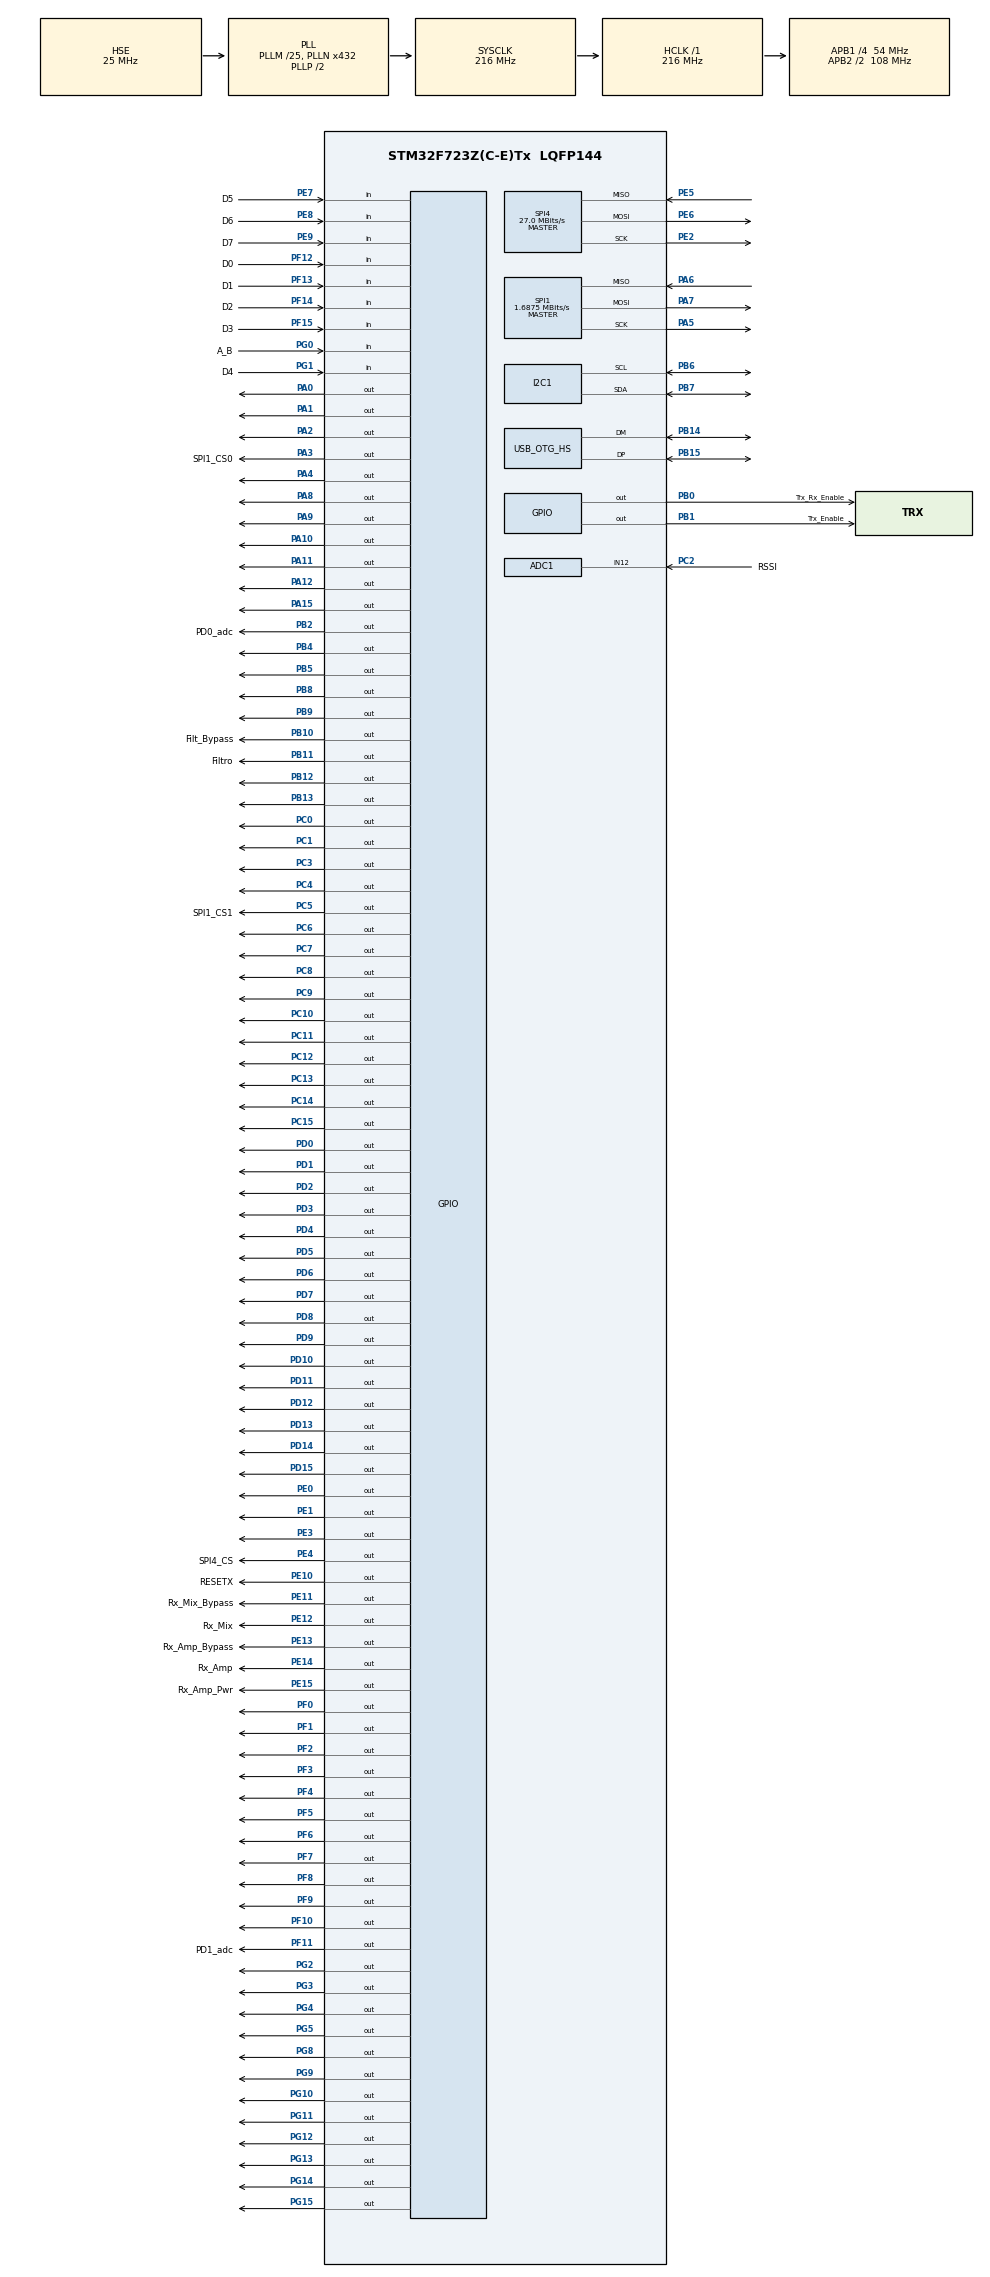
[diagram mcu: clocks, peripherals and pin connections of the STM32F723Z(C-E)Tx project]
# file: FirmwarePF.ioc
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PH0-OSC_IN.Signal=RCC_OSC_IN
SPI4.VirtualType=VM_MASTER
NVIC.I2C1_EV_IRQn=true\:0\:0\:false\:false\:true\:true\:true
SPI1.VirtualType=VM_MASTER
PG4.Signal=GPIO_Output
PG8.Signal=GPIO_Output
PC12.Signal=GPIO_Output
PG0.Signal=GPIO_Input
PA3.GPIO_Speed=GPIO_SPEED_FREQ_VERY_HIGH
PB13.Signal=GPIO_Output
PG13.Signal=GPIO_Output
RCC.SYSCLKSource=RCC_SYSCLKSOURCE_PLLCLK
PF7.Signal=GPIO_Output
SPI1.Direction=SPI_DIRECTION_2LINES
PE2.Mode=Full_Duplex_Master
PD4.Signal=GPIO_Output
RCC.APB2TimFreq_Value=216000000
PB6.Signal=I2C1_SCL
PC7.Signal=GPIO_Output
PB6.Mode=I2C
SPI1.CalculateBaudRate=1.6875 MBits/s
PC3.Signal=GPIO_Output
PD0.Signal=GPIO_Output
PD8.Signal=GPIO_Output
PE5.Signal=SPI4_MISO
PE1.Signal=GPIO_Output
PB2.Signal=GPIO_Output
PB3.Mode=Trace_Asynchronous_SW
PF12.GPIO_Label=D0
PE9.Signal=GPIO_Input
PB14.Mode=Internal_Phy_Device
PB1.GPIO_Label=Trx_Enable
SPI1.DataSize=SPI_DATASIZE_8BIT
PE4.GPIO_Label=SPI4_CS
PE2.Signal=SPI4_SCK
PA8.Signal=GPIO_Output
PF3.Signal=GPIO_Output
NVIC.I2C1_ER_IRQn=true\:0\:0\:false\:false\:true\:true\:true
PE10.Signal=GPIO_Output
Mcu.Package=LQFP144
PB9.Signal=GPIO_Output
PB1.Signal=GPIO_Output
PD12.Signal=GPIO_Output
PA10.Signal=GPIO_Output
PE12.GPIO_Label=Rx_Mix
RCC.APB2CLKDivider=RCC_HCLK_DIV2
PF14.Signal=GPIO_Input
RCC.APB1TimFreq_Value=108000000
PE10.GPIO_Label=RESETX
PD15.Signal=GPIO_Output
NVIC.RCC_IRQn=true\:0\:0\:false\:false\:true\:true\:false
PA5.Mode=Full_Duplex_Master
PG12.Signal=GPIO_Output
REXTPHYHS.Signal=USB_OTG_HS_REXTPHYHS
PG5.Signal=GPIO_Output
PG9.Signal=GPIO_Output
PC13.Signal=GPIO_Output
PD3.Signal=GPIO_Output
PC2.Signal=ADCx_IN12
PC6.Signal=GPIO_Output
PB11.GPIO_Label=Filtro
PD7.Signal=GPIO_Output
PD1.Signal=GPIO_Output
PF14.GPIO_Label=D2
PC0.Signal=GPIO_Output
RCC.APB1CLKDivider=RCC_HCLK_DIV4
PC14-OSC32_IN.Signal=GPIO_Output
PF13.GPIO_Label=D1
PA0-WKUP.Signal=GPIO_Output
PG10.Signal=GPIO_Output
PD10.Signal=GPIO_Output
PE8.GPIO_Label=D6
PA9.Signal=GPIO_Output
I2C1.Timing=0x20404768
PE9.GPIO_Label=D7
SPI4.NSSPMode=SPI_NSS_PULSE_DISABLE
PB10.Signal=GPIO_Output
PB14.Signal=USB_OTG_HS_DM
PA5.Signal=SPI1_SCK
NVIC.SPI1_IRQn=true\:0\:0\:false\:false\:true\:true\:true
PE14.Signal=GPIO_Output
PE6.Mode=Full_Duplex_Master
PE15.Signal=GPIO_Output
PE8.Signal=GPIO_Input
SPI1.Mode=SPI_MODE_MASTER
PF13.Signal=GPIO_Input
PA13.Mode=Trace_Asynchronous_SW
SPI1.NSSPMode=SPI_NSS_PULSE_DISABLE
PA4.Signal=GPIO_Output
PB5.Signal=GPIO_Output
ADC1.master=1
PE13.GPIO_Label=Rx_Amp_Bypass
PD11.Signal=GPIO_Output
PA11.Signal=GPIO_Output
ProjectManager.HeapSize=0x200
PF9.Signal=GPIO_Output
NVIC.PriorityGroup=NVIC_PRIORITYGROUP_4
PC5.GPIO_Speed=GPIO_SPEED_FREQ_VERY_HIGH
PE3.Signal=GPIO_Output
PE4.PinState=GPIO_PIN_SET
PA3.PinState=GPIO_PIN_SET
PF4.Signal=GPIO_Output
PD2.Signal=GPIO_Output
PB0.Signal=GPIO_Output
PC1.Signal=GPIO_Output
Mcu.Family=STM32F7
NVIC.OTG_HS_IRQn=true\:0\:0\:false\:false\:true\:false\:true
PA6.Mode=Full_Duplex_Master
VP_USB_DEVICE_VS_USB_DEVICE_CDC_HS.Mode=CDC_HS
RCC.CortexFreq_Value=216000000
PG2.Signal=GPIO_Output
PE11.GPIO_Label=Rx_Mix_Bypass
PC10.Signal=GPIO_Output
SPI4.Direction=SPI_DIRECTION_2LINES
PB0.GPIO_Label=Trx_Rx_Enable
PB11.Signal=GPIO_Output
PB15.Signal=USB_OTG_HS_DP
PG11.Signal=GPIO_Output
PG15.Signal=GPIO_Output
ProjectManager.StackSize=0x400
PD13.Signal=GPIO_Output
NVIC.ADC_IRQn=true\:0\:0\:false\:false\:true\:true\:true
PA12.Signal=GPIO_Output
SPI4.Mode=SPI_MODE_MASTER
ADC1.Channel-3\#ChannelRegularConversion=ADC_CHANNEL_12
RCC.HCLKFreq_Value=216000000
PF11.GPIO_Label=PD1_adc
PF12.Signal=GPIO_Input
USB_DEVICE.VirtualMode-CDC_HS=Cdc
RCC.AHBFreq_Value=216000000
PH0-OSC_IN.Mode=HSE-External-Clock-Source
RCC.HSE_VALUE=25000000
PE13.Signal=GPIO_Output
PA14.Mode=Trace_Asynchronous_SW
PE4.GPIO_Speed=GPIO_SPEED_FREQ_VERY_HIGH
PF11.Signal=GPIO_Output
PB7.Signal=I2C1_SDA
USB_OTG_HS.dma_enable=ENABLE
PE4.Signal=GPIO_Output
SPI4.BaudRatePrescaler=SPI_BAUDRATEPRESCALER_4
PH1-OSC_OUT.Mode=HSE-External-Clock-Source
PA6.Signal=SPI1_MISO
PA15.Signal=GPIO_Output
USB_DEVICE.CLASS_NAME_HS=CDC
PF8.Signal=GPIO_Output
PG0.GPIO_Label=A_B
PF5.Signal=GPIO_Output
USB_DEVICE.VirtualModeHS=Cdc_HS
PF0.Signal=GPIO_Output
PC5.Signal=GPIO_Output
PE7.Signal=GPIO_Input
PD6.Signal=GPIO_Output
SPI1.BaudRatePrescaler=SPI_BAUDRATEPRESCALER_64
PC2.GPIO_Label=RSSI
REXTPHYHS.Mode=Internal_Phy_Device
PB4.Signal=GPIO_Output
PA3.Signal=GPIO_Output
PA7.Mode=Full_Duplex_Master
SPI4.DataSize=SPI_DATASIZE_16BIT
PG3.Signal=GPIO_Output
PG1.Signal=GPIO_Input
PC11.Signal=GPIO_Output
PC8.Signal=GPIO_Output
PC4.Signal=GPIO_Output
PE14.GPIO_Label=Rx_Amp
PD9.Signal=GPIO_Output
PD5.Signal=GPIO_Output
PA13.Signal=SYS_JTMS-SWDIO
SH.ADCx_IN12.0=ADC1_IN12,IN12
PE15.GPIO_Label=Rx_Amp_Pwr
PF6.Signal=GPIO_Output
ProjectManager.TargetToolchain=STM32CubeIDE
PB10.GPIO_Label=Filt_Bypass
PF2.Signal=GPIO_Output
RCC.USBFreq_Value=48000000
PE11.Signal=GPIO_Output
RCC.LSE_VALUE=32768
PC15-OSC32_OUT.Signal=GPIO_Output
PA1.Signal=GPIO_Output
PG14.Signal=GPIO_Output
board=custom
RCC.VCOOutputFreq_Value=432000000
PG1.GPIO_Label=D4
PB15.Mode=Internal_Phy_Device
NVIC.OTG_HS_EP1_OUT_IRQn=true\:0\:0\:false\:false\:true\:true\:true
RCC.APB2Freq_Value=108000000
PF10.Signal=GPIO_Output
PE5.Mode=Full_Duplex_Master
USB_DEVICE.USBD_SELF_POWERED-CDC_HS=0
PH1-OSC_OUT.Signal=RCC_OSC_OUT
PF15.GPIO_Label=D3
PF15.Signal=GPIO_Input
SPI4.CalculateBaudRate=27.0 MBits/s
PF1.Signal=GPIO_Output
PE6.Signal=SPI4_MOSI
Mcu.Name=STM32F723Z(C-E)Tx
PE0.Signal=GPIO_Output
PE7.GPIO_Label=D5
PE12.Signal=GPIO_Output
PA2.Signal=GPIO_Output
NVIC.OTG_HS_EP1_IN_IRQn=true\:0\:0\:false\:false\:true\:true\:true
PD14.Signal=GPIO_Output
PB3.Signal=SYS_JTDO-SWO
RCC.SYSCLKFreq_VALUE=216000000
PC5.PinState=GPIO_PIN_SET
ADC1.Rank-3\#ChannelRegularConversion=1
ADC1.SamplingTime-3\#ChannelRegularConversion=ADC_SAMPLETIME_3CYCLES
USB_OTG_HS.VirtualMode=Int_Phy_Device
PC5.GPIO_Label=SPI1_CS1
USB_DEVICE.USBD_LPM_ENABLED-CDC_HS=0
PB7.Mode=I2C
PA14.Signal=SYS_JTCK-SWCLK
PB2.GPIO_Label=PD0_adc
RCC.HSI_VALUE=16000000
RCC.PLLQ=9
ADC1.NbrOfConversionFlag=1
RCC.PLLM=25
RCC.PLLN=432
PB8.Signal=GPIO_Output
PC9.Signal=GPIO_Output
RCC.APB1Freq_Value=54000000
PB12.Signal=GPIO_Output
PA3.GPIO_Label=SPI1_CS0
PA7.Signal=SPI1_MOSI

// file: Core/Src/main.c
/* USER CODE BEGIN Header */
/**
  ******************************************************************************
  * @file           : main.c
  * @brief          : Main program body
  ******************************************************************************
  * @attention
  *
  * <h2><center>&copy; Copyright (c) 2021 STMicroelectronics.
  * All rights reserved.</center></h2>
  *
  * This software component is licensed by ST under Ultimate Liberty license
  * SLA0044, the "License"; You may not use this file except in compliance with
  * the License. You may obtain a copy of the License at:
  *                             www.st.com/SLA0044
  *
  ******************************************************************************
  */
/* USER CODE END Header */
#include "main.h"
#include "usb_device.h"

/* USER CODE BEGIN Includes */
#include "usbd_cdc_if.h"
/*#include "gen_clock.h"
#include "max2837.h"
#include "rffc5072.h"
#include "utils.h"*/
//#include "i2c-lcd.h"
/* USER CODE END Includes */

ADC_HandleTypeDef hadc1;

I2C_HandleTypeDef hi2c1;

SPI_HandleTypeDef hspi1;
SPI_HandleTypeDef hspi4;

/* USER CODE BEGIN PV */
genclk_st clockg;
max2837_st transceiver;
rffc5072_st mixer;

uint8_t max2837_temperature;
uint16_t max2837_rssi;
/* USER CODE END PV */

void SystemClock_Config(void);
static void MX_GPIO_Init(void);
static void MX_SPI1_Init(void);
static void MX_I2C1_Init(void);
static void MX_SPI4_Init(void);
static void MX_ADC1_Init(void);

/* USER CODE BEGIN 0 */
void HAL_SPI_TxCpltCallback(SPI_HandleTypeDef *hspi){
	if(mixer.mixer_read_flg){
		if((HAL_SPI_Receive_IT(mixer.spiHandle, mixer.rxDataBuf, sizeof(mixer.rxDataBuf))) == HAL_OK){
		}
		else{
			mixer.mixer_read_flg = 0;
			spi_disable(mixer.CS_bank, mixer.CS_pin);
			//lcd_send_string("Mix_r_err SPI Rx");
		}
	}
	else if(mixer.mixer_write_flg){
		mixer.mixer_write_flg = 0;
		mixer.regs_values[mixer.current_addr] = mixer.txData_temp;
		spi_disable(mixer.CS_bank, mixer.CS_pin);
	}

	if(transceiver.transceiver_write_flg){
		transceiver.transceiver_write_flg = 0;
		transceiver.regs_values[transceiver.current_addr] = transceiver.txData_temp;
		spi_disable(transceiver.CS_bank, transceiver.CS_pin);
	}
}

void HAL_SPI_RxCpltCallback(SPI_HandleTypeDef *hspi){
	if(mixer.mixer_read_flg){
		mixer.regs_values[mixer.current_addr] = (mixer.rxDataBuf[0] << 8) | mixer.rxDataBuf[1];
		mixer.mixer_read_flg = 0;
		spi_disable(mixer.CS_bank, mixer.CS_pin);
	}
}

void HAL_SPI_TxRxCpltCallback(SPI_HandleTypeDef *hspi){
	if(transceiver.transceiver_read_flg){
		transceiver.transceiver_read_flg = 0;
		transceiver.regs_values[transceiver.current_addr] = (transceiver.rxDataBuf[1] << 2) | transceiver.rxDataBuf[2];
		spi_disable(transceiver.CS_bank, transceiver.CS_pin);
	}
}

/* USER CODE END 0 */

int main(void)
{

  /* MCU Configuration--------------------------------------------------------*/

  /* Reset of all peripherals, Initializes the Flash interface and the Systick. */
  HAL_Init();

  /* Configure the system clock */
  SystemClock_Config();

  /* Initialize all configured peripherals */
  MX_GPIO_Init();
  MX_SPI1_Init();
  MX_USB_DEVICE_Init();
  MX_I2C1_Init();
  MX_SPI4_Init();
  MX_ADC1_Init();
  /* USER CODE BEGIN 2 */

  gpio_init();
  genclk_init(&clockg, &hi2c1);
  max2837_init(&transceiver, &hspi1, SPI1_CS1_GPIO_Port, SPI1_CS1_Pin, Trx_Enable_GPIO_Port, Trx_Enable_Pin, Trx_Rx_Enable_Pin);
  rffc5072_init(&mixer, &hspi1, SPI1_CS0_GPIO_Port, SPI1_CS0_Pin);
  //lcd_init();
  genclk_fod_settings(&clockg, 1, 24);
  HAL_Delay(200);
  genclk_fod_settings(&clockg, 2, 43);
  HAL_Delay(200);
  genclk_fod_settings(&clockg, 3, 38);
  HAL_Delay(200);
  genclk_fod_settings(&clockg, 4, 49);

  /* USER CODE END 2 */

  /* Infinite loop */
  while (1)
  {

  }
}

void SystemClock_Config(void)
{
  RCC_OscInitTypeDef RCC_OscInitStruct = {0};
  RCC_ClkInitTypeDef RCC_ClkInitStruct = {0};
  RCC_PeriphCLKInitTypeDef PeriphClkInitStruct = {0};

  /** Configure the main internal regulator output voltage
  */
  __HAL_RCC_PWR_CLK_ENABLE();
  __HAL_PWR_VOLTAGESCALING_CONFIG(PWR_REGULATOR_VOLTAGE_SCALE1);
  /** Initializes the RCC Oscillators according to the specified parameters
  * in the RCC_OscInitTypeDef structure.
  */
  RCC_OscInitStruct.OscillatorType = RCC_OSCILLATORTYPE_HSE;
  RCC_OscInitStruct.HSEState = RCC_HSE_BYPASS;
  RCC_OscInitStruct.PLL.PLLState = RCC_PLL_ON;
  RCC_OscInitStruct.PLL.PLLSource = RCC_PLLSOURCE_HSE;
  RCC_OscInitStruct.PLL.PLLM = 25;
  RCC_OscInitStruct.PLL.PLLN = 432;
  RCC_OscInitStruct.PLL.PLLP = RCC_PLLP_DIV2;
  RCC_OscInitStruct.PLL.PLLQ = 9;
  if (HAL_RCC_OscConfig(&RCC_OscInitStruct) != HAL_OK)
  {
    Error_Handler();
  }
  /** Activate the Over-Drive mode
  */
  if (HAL_PWREx_EnableOverDrive() != HAL_OK)
  {
    Error_Handler();
  }
  /** Initializes the CPU, AHB and APB buses clocks
  */
  RCC_ClkInitStruct.ClockType = RCC_CLOCKTYPE_HCLK|RCC_CLOCKTYPE_SYSCLK
                              |RCC_CLOCKTYPE_PCLK1|RCC_CLOCKTYPE_PCLK2;
  RCC_ClkInitStruct.SYSCLKSource = RCC_SYSCLKSOURCE_PLLCLK;
  RCC_ClkInitStruct.AHBCLKDivider = RCC_SYSCLK_DIV1;
  RCC_ClkInitStruct.APB1CLKDivider = RCC_HCLK_DIV4;
  RCC_ClkInitStruct.APB2CLKDivider = RCC_HCLK_DIV2;

  if (HAL_RCC_ClockConfig(&RCC_ClkInitStruct, FLASH_LATENCY_7) != HAL_OK)
  {
    Error_Handler();
  }
  PeriphClkInitStruct.PeriphClockSelection = RCC_PERIPHCLK_I2C1|RCC_PERIPHCLK_CLK48;
  PeriphClkInitStruct.I2c1ClockSelection = RCC_I2C1CLKSOURCE_PCLK1;
  PeriphClkInitStruct.Clk48ClockSelection = RCC_CLK48SOURCE_PLL;
  if (HAL_RCCEx_PeriphCLKConfig(&PeriphClkInitStruct) != HAL_OK)
  {
    Error_Handler();
  }
}

static void MX_ADC1_Init(void)
{

  ADC_ChannelConfTypeDef sConfig = {0};

  /** Configure the global features of the ADC (Clock, Resolution, Data Alignment and number of conversion)
  */
  hadc1.Instance = ADC1;
  hadc1.Init.ClockPrescaler = ADC_CLOCK_SYNC_PCLK_DIV4;
  hadc1.Init.Resolution = ADC_RESOLUTION_12B;
  hadc1.Init.ScanConvMode = ADC_SCAN_DISABLE;
  hadc1.Init.ContinuousConvMode = DISABLE;
  hadc1.Init.DiscontinuousConvMode = DISABLE;
  hadc1.Init.ExternalTrigConvEdge = ADC_EXTERNALTRIGCONVEDGE_NONE;
  hadc1.Init.ExternalTrigConv = ADC_SOFTWARE_START;
  hadc1.Init.DataAlign = ADC_DATAALIGN_RIGHT;
  hadc1.Init.NbrOfConversion = 1;
  hadc1.Init.DMAContinuousRequests = DISABLE;
  hadc1.Init.EOCSelection = ADC_EOC_SINGLE_CONV;
  if (HAL_ADC_Init(&hadc1) != HAL_OK)
  {
    Error_Handler();
  }
  /** Configure for the selected ADC regular channel its corresponding rank in the sequencer and its sample time.
  */
  sConfig.Channel = ADC_CHANNEL_12;
  sConfig.Rank = ADC_REGULAR_RANK_1;
  sConfig.SamplingTime = ADC_SAMPLETIME_3CYCLES;
  if (HAL_ADC_ConfigChannel(&hadc1, &sConfig) != HAL_OK)
  {
    Error_Handler();
  }

}

static void MX_I2C1_Init(void)
{

  hi2c1.Instance = I2C1;
  hi2c1.Init.Timing = 0x20404768;
  hi2c1.Init.OwnAddress1 = 0;
  hi2c1.Init.AddressingMode = I2C_ADDRESSINGMODE_7BIT;
  hi2c1.Init.DualAddressMode = I2C_DUALADDRESS_DISABLE;
  hi2c1.Init.OwnAddress2 = 0;
  hi2c1.Init.OwnAddress2Masks = I2C_OA2_NOMASK;
  hi2c1.Init.GeneralCallMode = I2C_GENERALCALL_DISABLE;
  hi2c1.Init.NoStretchMode = I2C_NOSTRETCH_DISABLE;
  if (HAL_I2C_Init(&hi2c1) != HAL_OK)
  {
    Error_Handler();
  }
  /** Configure Analogue filter
  */
  if (HAL_I2CEx_ConfigAnalogFilter(&hi2c1, I2C_ANALOGFILTER_ENABLE) != HAL_OK)
  {
    Error_Handler();
  }
  /** Configure Digital filter
  */
  if (HAL_I2CEx_ConfigDigitalFilter(&hi2c1, 0) != HAL_OK)
  {
    Error_Handler();
  }

}

static void MX_SPI1_Init(void)
{

  /* SPI1 parameter configuration*/
  hspi1.Instance = SPI1;
  hspi1.Init.Mode = SPI_MODE_MASTER;
  hspi1.Init.Direction = SPI_DIRECTION_2LINES;
  hspi1.Init.DataSize = SPI_DATASIZE_8BIT;
  hspi1.Init.CLKPolarity = SPI_POLARITY_LOW;
  hspi1.Init.CLKPhase = SPI_PHASE_1EDGE;
  hspi1.Init.NSS = SPI_NSS_SOFT;
  hspi1.Init.BaudRatePrescaler = SPI_BAUDRATEPRESCALER_64;
  hspi1.Init.FirstBit = SPI_FIRSTBIT_MSB;
  hspi1.Init.TIMode = SPI_TIMODE_DISABLE;
  hspi1.Init.CRCCalculation = SPI_CRCCALCULATION_DISABLE;
  hspi1.Init.CRCPolynomial = 7;
  hspi1.Init.CRCLength = SPI_CRC_LENGTH_DATASIZE;
  hspi1.Init.NSSPMode = SPI_NSS_PULSE_DISABLE;
  if (HAL_SPI_Init(&hspi1) != HAL_OK)
  {
    Error_Handler();
  }

}

static void MX_SPI4_Init(void)
{

  /* SPI4 parameter configuration*/
  hspi4.Instance = SPI4;
  hspi4.Init.Mode = SPI_MODE_MASTER;
  hspi4.Init.Direction = SPI_DIRECTION_2LINES;
  hspi4.Init.DataSize = SPI_DATASIZE_16BIT;
  hspi4.Init.CLKPolarity = SPI_POLARITY_LOW;
  hspi4.Init.CLKPhase = SPI_PHASE_1EDGE;
  hspi4.Init.NSS = SPI_NSS_SOFT;
  hspi4.Init.BaudRatePrescaler = SPI_BAUDRATEPRESCALER_4;
  hspi4.Init.FirstBit = SPI_FIRSTBIT_MSB;
  hspi4.Init.TIMode = SPI_TIMODE_DISABLE;
  hspi4.Init.CRCCalculation = SPI_CRCCALCULATION_DISABLE;
  hspi4.Init.CRCPolynomial = 7;
  hspi4.Init.CRCLength = SPI_CRC_LENGTH_DATASIZE;
  hspi4.Init.NSSPMode = SPI_NSS_PULSE_DISABLE;
  if (HAL_SPI_Init(&hspi4) != HAL_OK)
  {
    Error_Handler();
  }

}

static void MX_GPIO_Init(void)
{
  GPIO_InitTypeDef GPIO_InitStruct = {0};

  /* GPIO Ports Clock Enable */
  __HAL_RCC_GPIOE_CLK_ENABLE();
  __HAL_RCC_GPIOC_CLK_ENABLE();
  __HAL_RCC_GPIOF_CLK_ENABLE();
  __HAL_RCC_GPIOH_CLK_ENABLE();
  __HAL_RCC_GPIOA_CLK_ENABLE();
  __HAL_RCC_GPIOB_CLK_ENABLE();
  __HAL_RCC_GPIOG_CLK_ENABLE();
  __HAL_RCC_GPIOD_CLK_ENABLE();

  /*Configure GPIO pin Output Level */
  HAL_GPIO_WritePin(GPIOE, GPIO_PIN_3|RESETX_Pin|Rx_Mix_Bypass_Pin|Rx_Mix_Pin
                          |Rx_Amp_Bypass_Pin|Rx_Amp_Pin|Rx_Amp_Pwr_Pin|GPIO_PIN_0
                          |GPIO_PIN_1, GPIO_PIN_RESET);

  /*Configure GPIO pin Output Level */
  HAL_GPIO_WritePin(SPI4_CS_GPIO_Port, SPI4_CS_Pin, GPIO_PIN_SET);

  /*Configure GPIO pin Output Level */
  HAL_GPIO_WritePin(GPIOC, GPIO_PIN_13|GPIO_PIN_14|GPIO_PIN_15|GPIO_PIN_0
                          |GPIO_PIN_1|GPIO_PIN_3|GPIO_PIN_4|GPIO_PIN_6
                          |GPIO_PIN_7|GPIO_PIN_8|GPIO_PIN_9|GPIO_PIN_10
                          |GPIO_PIN_11|GPIO_PIN_12, GPIO_PIN_RESET);

  /*Configure GPIO pin Output Level */
  HAL_GPIO_WritePin(GPIOF, GPIO_PIN_0|GPIO_PIN_1|GPIO_PIN_2|GPIO_PIN_3
                          |GPIO_PIN_4|GPIO_PIN_5|GPIO_PIN_6|GPIO_PIN_7
                          |GPIO_PIN_8|GPIO_PIN_9|GPIO_PIN_10|PD1_adc_Pin, GPIO_PIN_RESET);

  /*Configure GPIO pin Output Level */
  HAL_GPIO_WritePin(GPIOA, GPIO_PIN_0|GPIO_PIN_1|GPIO_PIN_2|GPIO_PIN_4
                          |GPIO_PIN_8|GPIO_PIN_9|GPIO_PIN_10|GPIO_PIN_11
                          |GPIO_PIN_12|GPIO_PIN_15, GPIO_PIN_RESET);

  /*Configure GPIO pin Output Level */
  HAL_GPIO_WritePin(SPI1_CS0_GPIO_Port, SPI1_CS0_Pin, GPIO_PIN_SET);

  /*Configure GPIO pin Output Level */
  HAL_GPIO_WritePin(SPI1_CS1_GPIO_Port, SPI1_CS1_Pin, GPIO_PIN_SET);

  /*Configure GPIO pin Output Level */
  HAL_GPIO_WritePin(GPIOB, Trx_Rx_Enable_Pin|Trx_Enable_Pin|PD0_adc_Pin|Filt_Bypass_Pin
                          |Filtro_Pin|GPIO_PIN_12|GPIO_PIN_13|GPIO_PIN_4
                          |GPIO_PIN_5|GPIO_PIN_8|GPIO_PIN_9, GPIO_PIN_RESET);

  /*Configure GPIO pin Output Level */
  HAL_GPIO_WritePin(GPIOD, GPIO_PIN_8|GPIO_PIN_9|GPIO_PIN_10|GPIO_PIN_11
                          |GPIO_PIN_12|GPIO_PIN_13|GPIO_PIN_14|GPIO_PIN_15
                          |GPIO_PIN_0|GPIO_PIN_1|GPIO_PIN_2|GPIO_PIN_3
                          |GPIO_PIN_4|GPIO_PIN_5|GPIO_PIN_6|GPIO_PIN_7, GPIO_PIN_RESET);

  /*Configure GPIO pin Output Level */
  HAL_GPIO_WritePin(GPIOG, GPIO_PIN_2|GPIO_PIN_3|GPIO_PIN_4|GPIO_PIN_5
                          |GPIO_PIN_8|GPIO_PIN_9|GPIO_PIN_10|GPIO_PIN_11
                          |GPIO_PIN_12|GPIO_PIN_13|GPIO_PIN_14|GPIO_PIN_15, GPIO_PIN_RESET);

  /*Configure GPIO pins : PE3 RESETX_Pin Rx_Mix_Bypass_Pin Rx_Mix_Pin
                           Rx_Amp_Bypass_Pin Rx_Amp_Pin Rx_Amp_Pwr_Pin PE0
                           PE1 */
  GPIO_InitStruct.Pin = GPIO_PIN_3|RESETX_Pin|Rx_Mix_Bypass_Pin|Rx_Mix_Pin
                          |Rx_Amp_Bypass_Pin|Rx_Amp_Pin|Rx_Amp_Pwr_Pin|GPIO_PIN_0
                          |GPIO_PIN_1;
  GPIO_InitStruct.Mode = GPIO_MODE_OUTPUT_PP;
  GPIO_InitStruct.Pull = GPIO_NOPULL;
  GPIO_InitStruct.Speed = GPIO_SPEED_FREQ_LOW;
  HAL_GPIO_Init(GPIOE, &GPIO_InitStruct);

  /*Configure GPIO pin : SPI4_CS_Pin */
  GPIO_InitStruct.Pin = SPI4_CS_Pin;
  GPIO_InitStruct.Mode = GPIO_MODE_OUTPUT_PP;
  GPIO_InitStruct.Pull = GPIO_NOPULL;
  GPIO_InitStruct.Speed = GPIO_SPEED_FREQ_VERY_HIGH;
  HAL_GPIO_Init(SPI4_CS_GPIO_Port, &GPIO_InitStruct);

  /*Configure GPIO pins : PC13 PC14 PC15 PC0
                           PC1 PC3 PC4 PC6
                           PC7 PC8 PC9 PC10
                           PC11 PC12 */
  GPIO_InitStruct.Pin = GPIO_PIN_13|GPIO_PIN_14|GPIO_PIN_15|GPIO_PIN_0
                          |GPIO_PIN_1|GPIO_PIN_3|GPIO_PIN_4|GPIO_PIN_6
                          |GPIO_PIN_7|GPIO_PIN_8|GPIO_PIN_9|GPIO_PIN_10
                          |GPIO_PIN_11|GPIO_PIN_12;
  GPIO_InitStruct.Mode = GPIO_MODE_OUTPUT_PP;
  GPIO_InitStruct.Pull = GPIO_NOPULL;
  GPIO_InitStruct.Speed = GPIO_SPEED_FREQ_LOW;
  HAL_GPIO_Init(GPIOC, &GPIO_InitStruct);

  /*Configure GPIO pins : PF0 PF1 PF2 PF3
                           PF4 PF5 PF6 PF7
                           PF8 PF9 PF10 PD1_adc_Pin */
  GPIO_InitStruct.Pin = GPIO_PIN_0|GPIO_PIN_1|GPIO_PIN_2|GPIO_PIN_3
                          |GPIO_PIN_4|GPIO_PIN_5|GPIO_PIN_6|GPIO_PIN_7
                          |GPIO_PIN_8|GPIO_PIN_9|GPIO_PIN_10|PD1_adc_Pin;
  GPIO_InitStruct.Mode = GPIO_MODE_OUTPUT_PP;
  GPIO_InitStruct.Pull = GPIO_NOPULL;
  GPIO_InitStruct.Speed = GPIO_SPEED_FREQ_LOW;
  HAL_GPIO_Init(GPIOF, &GPIO_InitStruct);

  /*Configure GPIO pins : PA0 PA1 PA2 PA4
                           PA8 PA9 PA10 PA11
                           PA12 PA15 */
  GPIO_InitStruct.Pin = GPIO_PIN_0|GPIO_PIN_1|GPIO_PIN_2|GPIO_PIN_4
                          |GPIO_PIN_8|GPIO_PIN_9|GPIO_PIN_10|GPIO_PIN_11
                          |GPIO_PIN_12|GPIO_PIN_15;
  GPIO_InitStruct.Mode = GPIO_MODE_OUTPUT_PP;
  GPIO_InitStruct.Pull = GPIO_NOPULL;
  GPIO_InitStruct.Speed = GPIO_SPEED_FREQ_LOW;
  HAL_GPIO_Init(GPIOA, &GPIO_InitStruct);

  /*Configure GPIO pin : SPI1_CS0_Pin */
  GPIO_InitStruct.Pin = SPI1_CS0_Pin;
  GPIO_InitStruct.Mode = GPIO_MODE_OUTPUT_PP;
  GPIO_InitStruct.Pull = GPIO_NOPULL;
  GPIO_InitStruct.Speed = GPIO_SPEED_FREQ_VERY_HIGH;
  HAL_GPIO_Init(SPI1_CS0_GPIO_Port, &GPIO_InitStruct);

  /*Configure GPIO pin : SPI1_CS1_Pin */
  GPIO_InitStruct.Pin = SPI1_CS1_Pin;
  GPIO_InitStruct.Mode = GPIO_MODE_OUTPUT_PP;
  GPIO_InitStruct.Pull = GPIO_NOPULL;
  GPIO_InitStruct.Speed = GPIO_SPEED_FREQ_VERY_HIGH;
  HAL_GPIO_Init(SPI1_CS1_GPIO_Port, &GPIO_InitStruct);

  /*Configure GPIO pins : Trx_Rx_Enable_Pin Trx_Enable_Pin PD0_adc_Pin Filt_Bypass_Pin
                           Filtro_Pin PB12 PB13 PB4
                           PB5 PB8 PB9 */
  GPIO_InitStruct.Pin = Trx_Rx_Enable_Pin|Trx_Enable_Pin|PD0_adc_Pin|Filt_Bypass_Pin
                          |Filtro_Pin|GPIO_PIN_12|GPIO_PIN_13|GPIO_PIN_4
                          |GPIO_PIN_5|GPIO_PIN_8|GPIO_PIN_9;
  GPIO_InitStruct.Mode = GPIO_MODE_OUTPUT_PP;
  GPIO_InitStruct.Pull = GPIO_NOPULL;
  GPIO_InitStruct.Speed = GPIO_SPEED_FREQ_LOW;
  HAL_GPIO_Init(GPIOB, &GPIO_InitStruct);

  /*Configure GPIO pins : D0_Pin D1_Pin D2_Pin D3_Pin */
  GPIO_InitStruct.Pin = D0_Pin|D1_Pin|D2_Pin|D3_Pin;
  GPIO_InitStruct.Mode = GPIO_MODE_INPUT;
  GPIO_InitStruct.Pull = GPIO_NOPULL;
  HAL_GPIO_Init(GPIOF, &GPIO_InitStruct);

  /*Configure GPIO pins : A_B_Pin D4_Pin */
  GPIO_InitStruct.Pin = A_B_Pin|D4_Pin;
  GPIO_InitStruct.Mode = GPIO_MODE_INPUT;
  GPIO_InitStruct.Pull = GPIO_NOPULL;
  HAL_GPIO_Init(GPIOG, &GPIO_InitStruct);

  /*Configure GPIO pins : D5_Pin D6_Pin D7_Pin */
  GPIO_InitStruct.Pin = D5_Pin|D6_Pin|D7_Pin;
  GPIO_InitStruct.Mode = GPIO_MODE_INPUT;
  GPIO_InitStruct.Pull = GPIO_NOPULL;
  HAL_GPIO_Init(GPIOE, &GPIO_InitStruct);

  /*Configure GPIO pins : PD8 PD9 PD10 PD11
                           PD12 PD13 PD14 PD15
                           PD0 PD1 PD2 PD3
                           PD4 PD5 PD6 PD7 */
  GPIO_InitStruct.Pin = GPIO_PIN_8|GPIO_PIN_9|GPIO_PIN_10|GPIO_PIN_11
                          |GPIO_PIN_12|GPIO_PIN_13|GPIO_PIN_14|GPIO_PIN_15
                          |GPIO_PIN_0|GPIO_PIN_1|GPIO_PIN_2|GPIO_PIN_3
                          |GPIO_PIN_4|GPIO_PIN_5|GPIO_PIN_6|GPIO_PIN_7;
  GPIO_InitStruct.Mode = GPIO_MODE_OUTPUT_PP;
  GPIO_InitStruct.Pull = GPIO_NOPULL;
  GPIO_InitStruct.Speed = GPIO_SPEED_FREQ_LOW;
  HAL_GPIO_Init(GPIOD, &GPIO_InitStruct);

  /*Configure GPIO pins : PG2 PG3 PG4 PG5
                           PG8 PG9 PG10 PG11
                           PG12 PG13 PG14 PG15 */
  GPIO_InitStruct.Pin = GPIO_PIN_2|GPIO_PIN_3|GPIO_PIN_4|GPIO_PIN_5
                          |GPIO_PIN_8|GPIO_PIN_9|GPIO_PIN_10|GPIO_PIN_11
                          |GPIO_PIN_12|GPIO_PIN_13|GPIO_PIN_14|GPIO_PIN_15;
  GPIO_InitStruct.Mode = GPIO_MODE_OUTPUT_PP;
  GPIO_InitStruct.Pull = GPIO_NOPULL;
  GPIO_InitStruct.Speed = GPIO_SPEED_FREQ_LOW;
  HAL_GPIO_Init(GPIOG, &GPIO_InitStruct);

}

void Error_Handler(void)
{
  __disable_irq();
  while (1)
  {
  }
}

/************************ (C) COPYRIGHT STMicroelectronics *****END OF FILE****/
